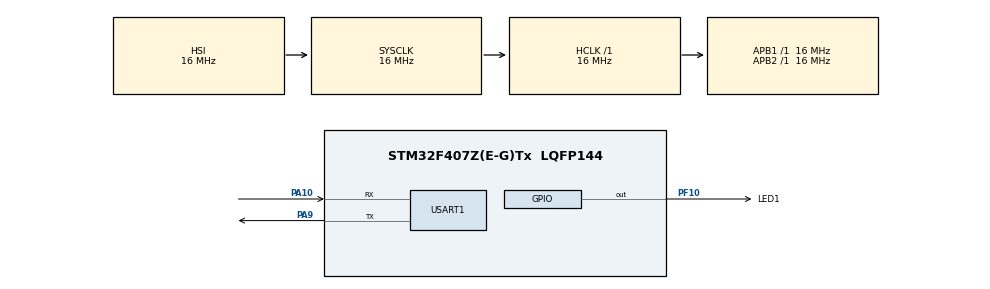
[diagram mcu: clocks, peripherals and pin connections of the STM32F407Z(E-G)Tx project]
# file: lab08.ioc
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Dma.Request0=USART1_RX
Dma.Request1=USART1_TX
Dma.USART1_RX.0.Direction=DMA_PERIPH_TO_MEMORY
Dma.USART1_RX.0.FIFOMode=DMA_FIFOMODE_DISABLE
Dma.USART1_RX.0.Instance=DMA2_Stream2
Dma.USART1_RX.0.MemDataAlignment=DMA_MDATAALIGN_BYTE
Dma.USART1_RX.0.MemInc=DMA_MINC_ENABLE
Dma.USART1_RX.0.Mode=DMA_NORMAL
Dma.USART1_RX.0.PeriphDataAlignment=DMA_PDATAALIGN_BYTE
Dma.USART1_RX.0.PeriphInc=DMA_PINC_DISABLE
Dma.USART1_RX.0.Priority=DMA_PRIORITY_LOW
Dma.USART1_TX.1.Direction=DMA_MEMORY_TO_PERIPH
Dma.USART1_TX.1.FIFOMode=DMA_FIFOMODE_DISABLE
Dma.USART1_TX.1.Instance=DMA2_Stream7
Dma.USART1_TX.1.MemDataAlignment=DMA_MDATAALIGN_BYTE
Dma.USART1_TX.1.MemInc=DMA_MINC_ENABLE
Dma.USART1_TX.1.Mode=DMA_NORMAL
Dma.USART1_TX.1.PeriphDataAlignment=DMA_PDATAALIGN_BYTE
Dma.USART1_TX.1.PeriphInc=DMA_PINC_DISABLE
Dma.USART1_TX.1.Priority=DMA_PRIORITY_LOW
Mcu.Family=STM32F4
Mcu.Name=STM32F407Z(E-G)Tx
Mcu.Package=LQFP144
NVIC.DMA2_Stream2_IRQn=true\:0\:0\:false\:true\:true\:2\:false\:true
NVIC.DMA2_Stream7_IRQn=true\:0\:0\:false\:true\:true\:1\:false\:true
NVIC.PriorityGroup=NVIC_PRIORITYGROUP_4
NVIC.USART1_IRQn=true\:0\:0\:false\:true\:true\:3\:true\:true
PA10.Mode=Asynchronous
PA10.Signal=USART1_RX
PA9.Mode=Asynchronous
PA9.Signal=USART1_TX
PF10.GPIO_Label=LED1
PF10.Signal=GPIO_Output
ProjectManager.HeapSize=0x200
ProjectManager.StackSize=0x400
ProjectManager.TargetToolchain=STM32CubeIDE
RCC.AHBFreq_Value=16000000
RCC.APB1Freq_Value=16000000
RCC.APB2Freq_Value=16000000
RCC.CortexFreq_Value=16000000
RCC.HSE_VALUE=25000000
RCC.HSI_VALUE=16000000
RCC.LSE_VALUE=32768
RCC.SYSCLKFreq_VALUE=16000000
RCC.VCOOutputFreq_Value=192000000
USART1.VirtualMode=VM_ASYNC
board=custom

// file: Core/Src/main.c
/* USER CODE BEGIN Header */
/**
  ******************************************************************************
  * @file           : main.c
  * @brief          : Main program body
  ******************************************************************************
  * @attention
  *
  * <h2><center>&copy; Copyright (c) 2022 STMicroelectronics.
  * All rights reserved.</center></h2>
  *
  * This software component is licensed by ST under BSD 3-Clause license,
  * the "License"; You may not use this file except in compliance with the
  * License. You may obtain a copy of the License at:
  *                        opensource.org/licenses/BSD-3-Clause
  *
  ******************************************************************************
  */
/* USER CODE END Header */
#include "main.h"

/* USER CODE BEGIN PTD */
#define BUF_SIZE	2000
/* USER CODE END PTD */

UART_HandleTypeDef huart1;
DMA_HandleTypeDef hdma_usart1_rx;
DMA_HandleTypeDef hdma_usart1_tx;

/* USER CODE BEGIN PV */
volatile uint8_t toggle = 0;
uint8_t uart_dma_buffer[BUF_SIZE] = {[0 ... BUF_SIZE - 3] = 'x',
									[BUF_SIZE - 2] = '\r',
									[BUF_SIZE - 1] = '\n'};
uint8_t uart_rx_buffer[1];
/* USER CODE END PV */

void SystemClock_Config(void);
static void MX_GPIO_Init(void);
static void MX_DMA_Init(void);
static void MX_USART1_UART_Init(void);
static void MX_NVIC_Init(void);

int main(void)
{

  /* MCU Configuration--------------------------------------------------------*/

  /* Reset of all peripherals, Initializes the Flash interface and the Systick. */
  HAL_Init();

  /* Configure the system clock */
  SystemClock_Config();

  /* Initialize all configured peripherals */
  MX_GPIO_Init();
  MX_DMA_Init();
  MX_USART1_UART_Init();

  /* Initialize interrupts */
  MX_NVIC_Init();

  /* Infinite loop */
  /* USER CODE BEGIN WHILE */
  HAL_UART_Transmit_IT(&huart1, (uint8_t *) "Welcome\n\r\tPress 0 or 1\n\r", sizeof("Welcome\n\r\tPress 0 or 1\n\r"));
  HAL_UART_Receive_DMA(&huart1, uart_rx_buffer, 1);

  while (1)
  {
    /* USER CODE END WHILE */

  }
}

void SystemClock_Config(void)
{
  RCC_OscInitTypeDef RCC_OscInitStruct = {0};
  RCC_ClkInitTypeDef RCC_ClkInitStruct = {0};

  /** Configure the main internal regulator output voltage
  */
  __HAL_RCC_PWR_CLK_ENABLE();
  __HAL_PWR_VOLTAGESCALING_CONFIG(PWR_REGULATOR_VOLTAGE_SCALE1);
  /** Initializes the RCC Oscillators according to the specified parameters
  * in the RCC_OscInitTypeDef structure.
  */
  RCC_OscInitStruct.OscillatorType = RCC_OSCILLATORTYPE_HSI;
  RCC_OscInitStruct.HSIState = RCC_HSI_ON;
  RCC_OscInitStruct.HSICalibrationValue = RCC_HSICALIBRATION_DEFAULT;
  RCC_OscInitStruct.PLL.PLLState = RCC_PLL_NONE;
  if (HAL_RCC_OscConfig(&RCC_OscInitStruct) != HAL_OK)
  {
    Error_Handler();
  }
  /** Initializes the CPU, AHB and APB buses clocks
  */
  RCC_ClkInitStruct.ClockType = RCC_CLOCKTYPE_HCLK|RCC_CLOCKTYPE_SYSCLK
                              |RCC_CLOCKTYPE_PCLK1|RCC_CLOCKTYPE_PCLK2;
  RCC_ClkInitStruct.SYSCLKSource = RCC_SYSCLKSOURCE_HSI;
  RCC_ClkInitStruct.AHBCLKDivider = RCC_SYSCLK_DIV1;
  RCC_ClkInitStruct.APB1CLKDivider = RCC_HCLK_DIV1;
  RCC_ClkInitStruct.APB2CLKDivider = RCC_HCLK_DIV1;

  if (HAL_RCC_ClockConfig(&RCC_ClkInitStruct, FLASH_LATENCY_0) != HAL_OK)
  {
    Error_Handler();
  }
}

/**
  * @brief NVIC Configuration.
  * @retval None
  */
static void MX_NVIC_Init(void)
{
  /* DMA2_Stream7_IRQn interrupt configuration */
  HAL_NVIC_SetPriority(DMA2_Stream7_IRQn, 0, 0);
  HAL_NVIC_EnableIRQ(DMA2_Stream7_IRQn);
  /* DMA2_Stream2_IRQn interrupt configuration */
  HAL_NVIC_SetPriority(DMA2_Stream2_IRQn, 0, 0);
  HAL_NVIC_EnableIRQ(DMA2_Stream2_IRQn);
  /* USART1_IRQn interrupt configuration */
  HAL_NVIC_SetPriority(USART1_IRQn, 0, 0);
  HAL_NVIC_EnableIRQ(USART1_IRQn);
}

static void MX_USART1_UART_Init(void)
{

  huart1.Instance = USART1;
  huart1.Init.BaudRate = 115200;
  huart1.Init.WordLength = UART_WORDLENGTH_8B;
  huart1.Init.StopBits = UART_STOPBITS_1;
  huart1.Init.Parity = UART_PARITY_NONE;
  huart1.Init.Mode = UART_MODE_TX_RX;
  huart1.Init.HwFlowCtl = UART_HWCONTROL_NONE;
  huart1.Init.OverSampling = UART_OVERSAMPLING_16;
  if (HAL_UART_Init(&huart1) != HAL_OK)
  {
    Error_Handler();
  }

}

static void MX_DMA_Init(void)
{

  /* DMA controller clock enable */
  __HAL_RCC_DMA2_CLK_ENABLE();

}

static void MX_GPIO_Init(void)
{
  GPIO_InitTypeDef GPIO_InitStruct = {0};

  /* GPIO Ports Clock Enable */
  __HAL_RCC_GPIOF_CLK_ENABLE();
  __HAL_RCC_GPIOA_CLK_ENABLE();

  /*Configure GPIO pin Output Level */
  HAL_GPIO_WritePin(LED1_GPIO_Port, LED1_Pin, GPIO_PIN_RESET);

  /*Configure GPIO pin : LED1_Pin */
  GPIO_InitStruct.Pin = LED1_Pin;
  GPIO_InitStruct.Mode = GPIO_MODE_OUTPUT_PP;
  GPIO_InitStruct.Pull = GPIO_NOPULL;
  GPIO_InitStruct.Speed = GPIO_SPEED_FREQ_LOW;
  HAL_GPIO_Init(LED1_GPIO_Port, &GPIO_InitStruct);

}

/* USER CODE BEGIN 4 */
void HAL_UART_RxCpltCallback(UART_HandleTypeDef *huart)
{
	if (uart_rx_buffer[0] == '0') {
		HAL_UART_AbortTransmit(&huart1);

		HAL_UART_Transmit(&huart1, (uint8_t *) "\n\r", 2, 100);
		HAL_UART_Transmit(&huart1, uart_rx_buffer, 1, 100);
		HAL_UART_Transmit(&huart1, (uint8_t*) "\n\rStop\n\r",
				sizeof("\n\rStop\n\r"), 100);
	}

	else if (uart_rx_buffer[0] == '1') {
		HAL_UART_Transmit(&huart1, (uint8_t *) "\n\r", 2, 100);
		HAL_UART_Transmit(&huart1, uart_rx_buffer, 1, 100);
		HAL_UART_Transmit(&huart1, (uint8_t*) "\n\rStart\n\r",
				sizeof("\n\rStart\n\r"), 100);

		HAL_UART_Transmit_DMA(&huart1, uart_dma_buffer, 2000);
	}

	else if (uart_rx_buffer[0] != '0' && uart_rx_buffer[0] != '1') {
		HAL_UART_Transmit(&huart1, (uint8_t*) "\n\rPress 0 or 1\n\r",
				sizeof("\n\rPress 0 or 1\n\r"), 100);
	}

	HAL_UART_Receive_DMA(&huart1, uart_rx_buffer, 1);
}

void HAL_UART_TxCpltCallback(UART_HandleTypeDef *huart)
{
  uint16_t i;
  toggle = !toggle;

  for(i = 1000; i < 1998; i++)
  {
    if(toggle)
      uart_dma_buffer[i] = '&';
    else
      uart_dma_buffer[i] = 'z';
  }

  uart_dma_buffer[1998] = '\r';
  uart_dma_buffer[1999] = '\n';

  HAL_UART_Transmit_DMA(&huart1, uart_dma_buffer, 2000);
  HAL_GPIO_TogglePin(LED1_GPIO_Port, LED1_Pin);
}

void HAL_UART_TxHalfCpltCallback(UART_HandleTypeDef *huart)
{
  uint16_t i;

  for(i = 0; i < 1000; i++)
  {
    if(toggle)
      uart_dma_buffer[i] = 'y';
    else
      uart_dma_buffer[i] = '|';
  }
}

/* USER CODE END 4 */

void Error_Handler(void)
{
  __disable_irq();
  while (1)
  {
  }
}

/************************ (C) COPYRIGHT STMicroelectronics *****END OF FILE****/
